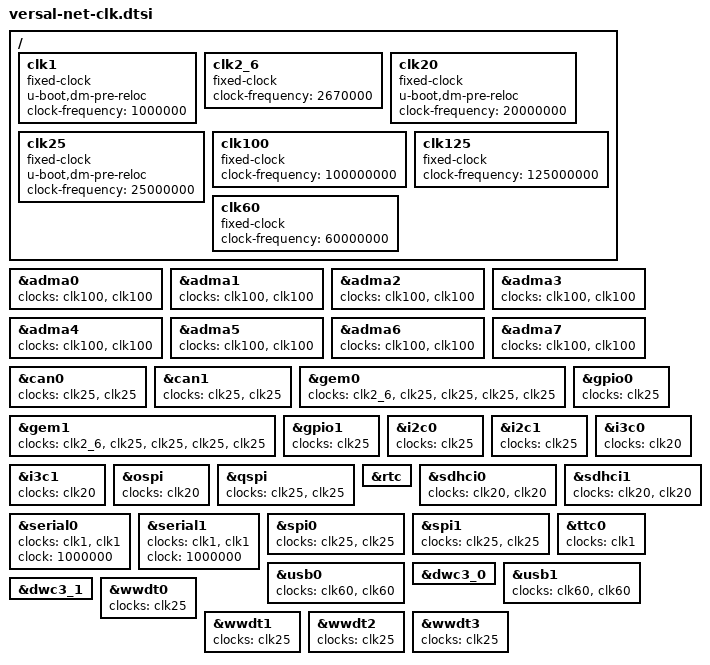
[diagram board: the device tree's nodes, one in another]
// SPDX-License-Identifier: GPL-2.0
/*
 * dts file for Xilinx Versal NET fixed clock
 *
 * (C) Copyright 2022, Xilinx, Inc.
 *
 * Michal Simek <michal.simek@amd.com>
 */
 
/ {
	clk1: clk1 {
		u-boot,dm-pre-reloc;
		compatible = "fixed-clock";
		#clock-cells = <0>;
		clock-frequency = <1000000>;
	};

	clk2_6: clk2_6 {
		compatible = "fixed-clock";
		#clock-cells = <0>;
		clock-frequency = <2670000>;
	};

	clk20: clk20 {
		u-boot,dm-pre-reloc;
		compatible = "fixed-clock";
		#clock-cells = <0>;
		clock-frequency = <20000000>;
	};

	clk25: clk25 {
		u-boot,dm-pre-reloc;
		compatible = "fixed-clock";
		#clock-cells = <0>;
		clock-frequency = <25000000>;
	};

	clk100: clk100 {
		compatible = "fixed-clock";
		#clock-cells = <0>;
		clock-frequency = <100000000>;
	};

	clk125: clk125 {
		compatible = "fixed-clock";
		#clock-cells = <0>;
		clock-frequency = <125000000>;
	};

	clk60: clk60 {
		compatible = "fixed-clock";
		#clock-cells = <0>;
		clock-frequency = <60000000>;
	};
};

&adma0 {
	clocks = <&clk100>, <&clk100>;
};

&adma1 {
	clocks = <&clk100>, <&clk100>;
};

&adma2 {
	clocks = <&clk100>, <&clk100>;
};

&adma3 {
	clocks = <&clk100>, <&clk100>;
};

&adma4 {
	clocks = <&clk100>, <&clk100>;
};

&adma5 {
	clocks = <&clk100>, <&clk100>;
};

&adma6 {
	clocks = <&clk100>, <&clk100>;
};

&adma7 {
	clocks = <&clk100>, <&clk100>;
};

&can0 {
	clocks = <&clk25>, <&clk25>;
};

&can1 {
	clocks = <&clk25>, <&clk25>;
};

&gem0 {
	clocks = <&clk2_6>, <&clk25>, <&clk25>, <&clk25>, <&clk25>;
};

&gem1 {
	clocks = <&clk2_6>, <&clk25>, <&clk25>, <&clk25>, <&clk25>;
};


&gpio0 {
	clocks = <&clk25>;
};

&gpio1 {
	clocks = <&clk25>;
};

&i2c0 {
	clocks = <&clk25>;
};

&i2c1 {
	clocks = <&clk25>;
};

&i3c0 {
	clocks = <&clk20>;
};

&i3c1 {
	clocks = <&clk20>;
};

&ospi {
	clocks = <&clk20>;
};

&qspi {
	clocks = <&clk25>, <&clk25>;
};

&rtc {
	/* Nothing */
};

&sdhci0 {
	clocks = <&clk20>, <&clk20>;
};

&sdhci1 {
	clocks = <&clk20>, <&clk20>;
};

&serial0 {
	clocks = <&clk1>, <&clk1>;
	clock = <1000000>;
};

&serial1 {
	clocks = <&clk1>, <&clk1>;
	clock = <1000000>;
};

&spi0 {
	clocks = <&clk25>, <&clk25>;
};

&spi1 {
	clocks = <&clk25>, <&clk25>;
};

&ttc0 {
	clocks = <&clk1>;
};

&usb0 {
	clocks = <&clk60>, <&clk60>;
};

&dwc3_0 {
	/* Nothing */
};

&usb1 {
	clocks = <&clk60>, <&clk60>;
};

&dwc3_1 {
	/* Nothing */
};

&wwdt0 {
	clocks = <&clk25>;
};

&wwdt1 {
	clocks = <&clk25>;
};

&wwdt2 {
	clocks = <&clk25>;
};

&wwdt3 {
	clocks = <&clk25>;
};
